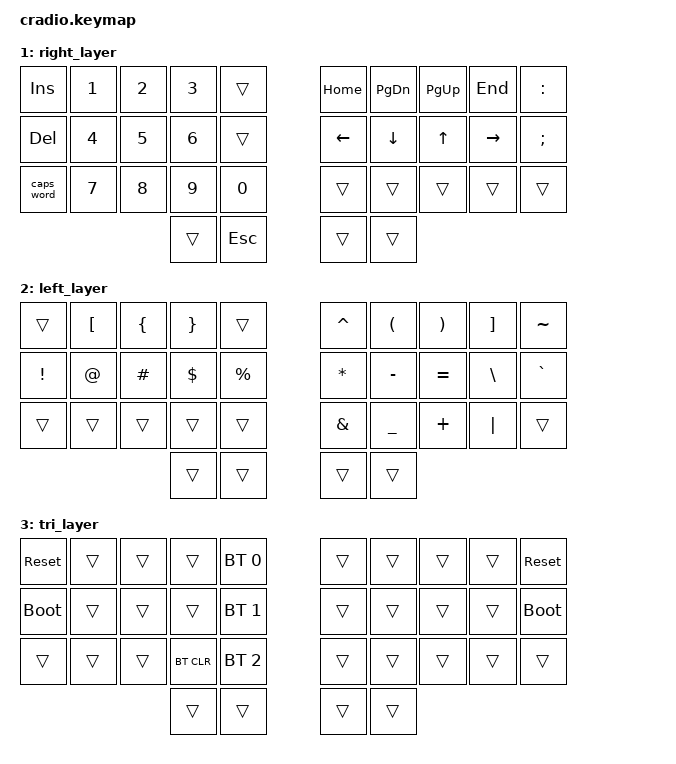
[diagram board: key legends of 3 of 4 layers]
// Copyright (c) 2022 The ZMK Contributors
// SPDX-License-Identifier: MIT

#include <behaviors.dtsi>
#include <dt-bindings/zmk/keys.h>
#include <dt-bindings/zmk/bt.h>

// Home row mods macro
#define HRML(k1,k2,k3,k4) &ht LSHFT k1  &ht LALT k2  &ht LCTRL k3  &ht LGUI k4
#define HRMR(k1,k2,k3,k4) &ht RGUI k1  &ht RCTRL k2  &ht RALT k3  &ht RSHFT k4

#define QWERTY 0
#define RAISE 1
#define LOWER 2
#define MOUSE 3

#define XXX &none
#define ___ &trans

/ {
    behaviors {
        ht: hold_tap {
            compatible = "zmk,behavior-hold-tap";
            #binding-cells = <2>;
            flavor = "tap-preferred";
            tapping-term-ms = <220>;
            quick-tap-ms = <150>;
            require-prior-idle-ms = <100>;
            bindings = <&kp>, <&kp>;
        };
    };

    conditional_layers {
        compatible = "zmk,conditional-layers";
        tri_layer {
            if-layers = <1 2>;
            then-layer = <3>;
        };
    };

    keymap {
        compatible = "zmk,keymap";
        default_layer {
            bindings = <
            &kp Q      &kp W      &kp E      &kp R      &kp T          &kp Y      &kp U      &kp I      &kp O      &kp P
            HRML(A,        S,         D,         F)     &kp G          &kp H      HRMR(J,        K,         L,        SQT)
            &kp Z      &kp X      &kp C      &kp V      &kp B          &kp N      &kp M      &kp COMMA  &kp DOT    &kp FSLH
                                            &lt LOWER TAB   &kp ENTER     &kp SPACE  &lt 1 BSPC
            >;
        };

        right_layer {
            bindings = <
            &kp INS    &kp N1     &kp N2     &kp N3     ___            &kp HOME   &kp PG_DN  &kp PG_UP  &kp END    &kp COLON
            &kp DEL    &kp N4     &kp N5     &kp N6     ___            &kp LEFT   &kp DOWN   &kp UP   &kp RIGHT   &kp SEMI
           &caps_word  &kp N7     &kp N8     &kp N9     &kp N0         ___        ___        ___        ___        ___
                                             ___        &kp ESC        ___        ___
            >;
        };

        left_layer {
            bindings = <
            ___        &kp LBKT   &kp LBRC   &kp RBRC   ___            &kp CARET  &kp LPAR   &kp RPAR   &kp RBKT   &kp TILDE
            &kp EXCL   &kp AT     &kp HASH   &kp DLLR   &kp PRCNT      &kp ASTRK  &kp MINUS  &kp EQUAL  &kp BSLH   &kp GRAVE
            ___        ___        ___        ___        ___            &kp AMPS   &kp UNDER  &kp PLUS   &kp PIPE   ___
                                             ___        ___            ___        ___
            >;
        };

        tri_layer {
            bindings = <
           &sys_reset  ___        ___        ___       &bt BT_SEL 0    ___        ___        ___        ___       &sys_reset
          &bootloader  ___        ___        ___       &bt BT_SEL 1    ___        ___        ___        ___       &bootloader
            ___        ___        ___       &bt BT_CLR &bt BT_SEL 2    ___        ___        ___        ___        ___
                                             ___        ___            ___        ___
            >;
        };
    };
};
/* vim: set ft=c tw=146: */
